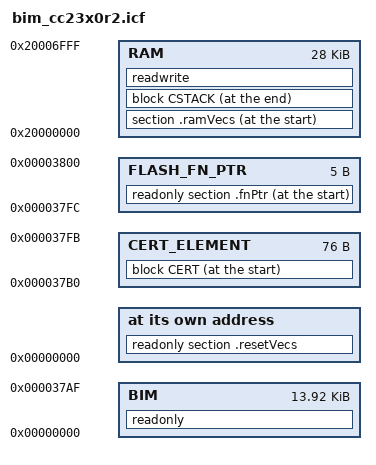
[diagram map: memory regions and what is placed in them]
/******************************************************************************

 @file  bim_cc23x0r2.icf

 @brief IAR ARM Linker Configuration File - BLE Application

        Imported Symbols
        Note: Linker defines are located in the IAR IDE project using
        --config_def in Options->Linker->Extra Options.

        CCxxxx:            Device Name (e.g. DeviceFamily_CC13X2)

        Exported Symbols
        Note: Can be used as externs in C code.

        STACK_TOP: Location of the top of RAM.

 Group: WCS, BTS
 Target Device: cc23xx

 ******************************************************************************
 
 Copyright (c) 2023-2025, Texas Instruments Incorporated
 All rights reserved.

 Redistribution and use in source and binary forms, with or without
 modification, are permitted provided that the following conditions
 are met:

 *  Redistributions of source code must retain the above copyright
    notice, this list of conditions and the following disclaimer.

 *  Redistributions in binary form must reproduce the above copyright
    notice, this list of conditions and the following disclaimer in the
    documentation and/or other materials provided with the distribution.

 *  Neither the name of Texas Instruments Incorporated nor the names of
    its contributors may be used to endorse or promote products derived
    from this software without specific prior written permission.

 THIS SOFTWARE IS PROVIDED BY THE COPYRIGHT HOLDERS AND CONTRIBUTORS "AS IS"
 AND ANY EXPRESS OR IMPLIED WARRANTIES, INCLUDING, BUT NOT LIMITED TO,
 THE IMPLIED WARRANTIES OF MERCHANTABILITY AND FITNESS FOR A PARTICULAR
 PURPOSE ARE DISCLAIMED. IN NO EVENT SHALL THE COPYRIGHT OWNER OR
 CONTRIBUTORS BE LIABLE FOR ANY DIRECT, INDIRECT, INCIDENTAL, SPECIAL,
 EXEMPLARY, OR CONSEQUENTIAL DAMAGES (INCLUDING, BUT NOT LIMITED TO,
 PROCUREMENT OF SUBSTITUTE GOODS OR SERVICES; LOSS OF USE, DATA, OR PROFITS;
 OR BUSINESS INTERRUPTION) HOWEVER CAUSED AND ON ANY THEORY OF LIABILITY,
 WHETHER IN CONTRACT, STRICT LIABILITY, OR TORT (INCLUDING NEGLIGENCE OR
 OTHERWISE) ARISING IN ANY WAY OUT OF THE USE OF THIS SOFTWARE,
 EVEN IF ADVISED OF THE POSSIBILITY OF SUCH DAMAGE.


 ******************************************************************************
 
 
 *****************************************************************************/

////////////////////////////////////////////////////////////////////////////////
// Memory Sizes
////////////////////////////////////////////////////////////////////////////////

define symbol FLASH_BASE            = 0x00000000;
define symbol RAM_BASE              = 0x20000000;
define symbol CCFG_BASE             = 0x4E020000;


define symbol RAM_SIZE            = 0x00007000; // 28K
define symbol FLASH_SIZE          = 0x00040000; // 256K
define symbol CCFG_SIZE           = 0x00000800; // 2K


////////////////////////////////////////////////////////////////////////////////
// Memory Definitions
////////////////////////////////////////////////////////////////////////////////

////////////////////////////////////////////////////////////////////////////////
// RAM
//

define symbol RAM_START         = RAM_BASE;
define symbol RAM_END           = RAM_BASE+RAM_SIZE-1;

////////////////////////////////////////////////////////////////////////////////
// Flash
//
define symbol WORD_SIZE             = 4;

define symbol PAGE_SIZE           = 0x800;

export symbol PAGE_SIZE;

if (isdefinedsymbol(PAGE_ALIGN))
{
  define symbol FLASH_MEM_ALIGN     = PAGE_SIZE;
}
else
{
  define symbol FLASH_MEM_ALIGN     = WORD_SIZE;
}

define symbol FLASH_START           = FLASH_BASE;

// leaving 4 bytes of buffer between CCFG and veify function pointer
define symbol FLASH_FNPTR_START    = FLASH_BASE + (PAGE_SIZE*7) - 4; // Last 4 bytes to be the fnptr
define symbol FLASH_FNPTR_END      = FLASH_FNPTR_START + 4; // 4 bytes function pointer

//storing cert element in fixed flash region,
//length of region is size of cert_element_t
define symbol CERT_END             = FLASH_FNPTR_START - 1;
define symbol CERT_SIZE            = 0x4C;        // For version 1 ECDSA-P256
define symbol CERT_START           = CERT_END - CERT_SIZE + 1;

define symbol CCFG_START           = CCFG_BASE;
define symbol CCFG_END             = CCFG_SIZE - 1;

// BIM is allocated at flash sector 0.
define symbol FLASH_PAGE_BIMSTART   = FLASH_BASE;
define symbol FLASH_PAGE_BIMEND     = CERT_START - 1;


////////////////////////////////////////////////////////////////////////////////
// Stack
//

define symbol STACK_SIZE           = 0x400;
define symbol STACK_START          = RAM_END;
define symbol STACK_END            = STACK_START - STACK_SIZE;
define block CSTACK with alignment = 8, size = STACK_SIZE { section .stack };

define symbol STACK_TOP            = RAM_END + 1;
export symbol STACK_TOP;

////////////////////////////////////////////////////////////////////////////////
// Flash Interrupt Vector Table
//

define symbol INTVEC_NUM_ENTRIES   = 50 + 1; // first entry is stack location
define symbol INTVEC_SIZE          = INTVEC_NUM_ENTRIES + 4;

////////////////////////////////////////////////////////////////////////////////
// Memory Regions
////////////////////////////////////////////////////////////////////////////////

define memory mem with size = 4G;

define region RAM                  = mem:[from RAM_START to RAM_END];

define region BIM                  = mem:[from FLASH_PAGE_BIMSTART
                                       to   FLASH_PAGE_BIMEND];

define region FLASH_FN_PTR         = mem:[from FLASH_FNPTR_START
                                       to   FLASH_FNPTR_END];

define region CERT_ELEMENT         = mem:[from CERT_START
                                          to CERT_END];

define region CCFG                 = mem:[from CCFG_START
                                          to CCFG_END];

////////////////////////////////////////////////////////////////////////////////
// CRC Specification Symbols
////////////////////////////////////////////////////////////////////////////////
/*
 * Define symbols required for CRC32 checksum generation within CCFG.
 * Post-build step example:
 * ielftool --checksum __ccfg_boot_cfg_crc32_end+1:4,crc32:1mi,0xFFFFFFFF;__ccfg_boot_cfg_crc32_begin-__ccfg_boot_cfg_crc32_end
 *          --checksum __ccfg_crc32_end+1:4,crc32:1mi,0xFFFFFFFF;__ccfg_crc32_begin-__ccfg_crc32_end
 *          --checksum __ccfg_user_record_crc32_end+1:4,crc32:1mi,0xFFFFFFFF;__ccfg_user_record_crc32_begin-__ccfg_user_record_crc32_end
 *          --checksum __ccfg_debug_cfg_crc32_end+1:4,crc32:1mi,0xFFFFFFFF;__ccfg_debug_cfg_crc32_begin-__ccfg_debug_cfg_crc32_end
 *          "$TARGET_PATH$" "$TARGET_PATH$"
 */
define exported symbol __ccfg_boot_cfg_crc32_begin      = 0x4E020000;
define exported symbol __ccfg_boot_cfg_crc32_end        = 0x4E02000B;
define exported symbol __ccfg_crc32_begin               = 0x4E020010;
define exported symbol __ccfg_crc32_end                 = 0x4E02074B;
define exported symbol __ccfg_user_record_crc32_begin   = 0x4E020750;
define exported symbol __ccfg_user_record_crc32_end     = 0x4E0207CB;
define exported symbol __ccfg_debug_cfg_crc32_begin     = 0x4E0207D0;
define exported symbol __ccfg_debug_cfg_crc32_end       = 0x4E0207FB;


////////////////////////////////////////////////////////////////////////////////
// Memory Placement
////////////////////////////////////////////////////////////////////////////////

// Function pointer table address
place at start of FLASH_FN_PTR   { readonly section .fnPtr };
keep                             { readonly section .fnPtr };

define block CERT                { ro section .cert_element};
keep                             { ro section .cert_element};
place at start of CERT_ELEMENT   { block CERT};

// Interrupt Vector Table
place at address mem:FLASH_PAGE_BIMSTART { readonly section .resetVecs };
keep                                     { readonly section .resetVecs };

// CCFG
place in CCFG                          { readonly section .ccfg   };
keep                                   { section .ccfg            };

// RAM Vector Table
place at start of RAM                  { section .ramVecs         };

// Stack
place at end of RAM                    { block CSTACK             };

place in BIM                           { readonly                 };
place in RAM                           { readwrite                };

////////////////////////////////////////////////////////////////////////////////
// Initialization
////////////////////////////////////////////////////////////////////////////////

initialize by copy  { readwrite };

do not initialize
{
  section .noinit,
  section .stack,
};

////////////////////////////////////////////////////////////////////////////////
